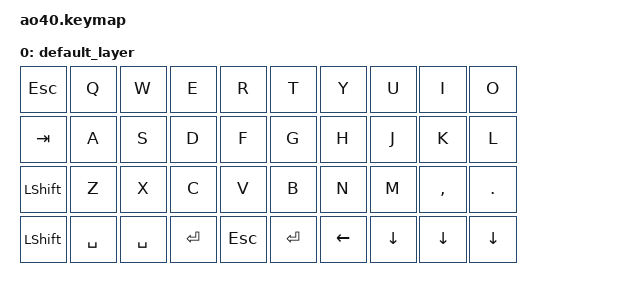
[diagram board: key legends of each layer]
#include <behaviors.dtsi>
#include <dt-bindings/zmk/keys.h>

/ {
    keymap {
        compatible = "zmk,keymap";

        default_layer {
            bindings = <
                &kp ESC    &kp Q    &kp W    &kp E     &kp R     &kp T     &kp Y     &kp U     &kp I     &kp O
                &kp TAB    &kp A    &kp S    &kp D     &kp F     &kp G     &kp H     &kp J     &kp K     &kp L
                &kp LSHIFT &kp Z    &kp X    &kp C     &kp V     &kp B     &kp N     &kp M     &kp COMMA &kp DOT
                &kp LSHIFT &kp SPACE&kp SPACE&kp RET   &kp ESC   &kp RET   &kp LEFT  &kp DOWN  &kp DOWN  &kp DOWN          
            >;
        };
    };
};
